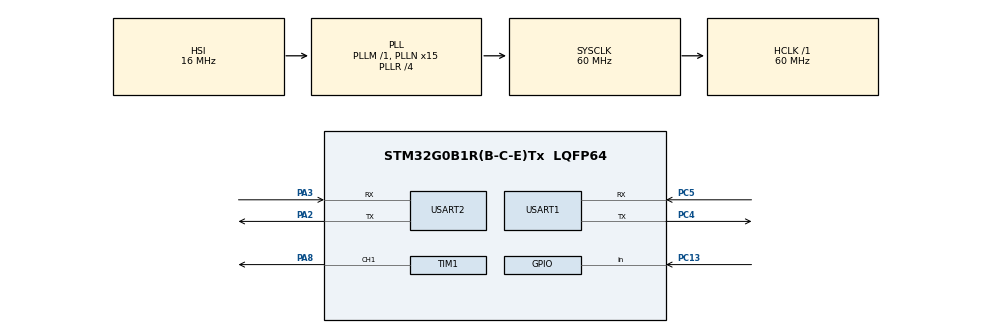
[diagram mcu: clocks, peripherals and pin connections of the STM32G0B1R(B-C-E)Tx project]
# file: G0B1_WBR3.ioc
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Dma.Request0=TIM1_CH1
Dma.TIM1_CH1.0.Direction=DMA_MEMORY_TO_PERIPH
Dma.TIM1_CH1.0.EventEnable=DISABLE
Dma.TIM1_CH1.0.Instance=DMA1_Channel1
Dma.TIM1_CH1.0.MemDataAlignment=DMA_MDATAALIGN_WORD
Dma.TIM1_CH1.0.MemInc=DMA_MINC_ENABLE
Dma.TIM1_CH1.0.Mode=DMA_NORMAL
Dma.TIM1_CH1.0.PeriphDataAlignment=DMA_PDATAALIGN_WORD
Dma.TIM1_CH1.0.PeriphInc=DMA_PINC_DISABLE
Dma.TIM1_CH1.0.Polarity=HAL_DMAMUX_REQ_GEN_RISING
Dma.TIM1_CH1.0.Priority=DMA_PRIORITY_HIGH
Dma.TIM1_CH1.0.RequestNumber=1
Dma.TIM1_CH1.0.SignalID=NONE
Dma.TIM1_CH1.0.SyncEnable=DISABLE
Dma.TIM1_CH1.0.SyncPolarity=HAL_DMAMUX_SYNC_NO_EVENT
Dma.TIM1_CH1.0.SyncRequestNumber=1
Dma.TIM1_CH1.0.SyncSignalID=NONE
Mcu.Family=STM32G0
Mcu.Name=STM32G0B1R(B-C-E)Tx
Mcu.Package=LQFP64
NVIC.DMA1_Channel1_IRQn=true\:0\:0\:false\:false\:true\:false\:true
NVIC.USART1_IRQn=true\:0\:0\:false\:false\:true\:true\:true
PA2.Mode=Asynchronous
PA2.Signal=USART2_TX
PA3.Mode=Asynchronous
PA3.Signal=USART2_RX
PA8.Signal=S_TIM1_CH1
PC13.Signal=GPIO_Input
PC4.Mode=Asynchronous
PC4.Signal=USART1_TX
PC5.Mode=Asynchronous
PC5.Signal=USART1_RX
ProjectManager.HeapSize=0x200
ProjectManager.StackSize=0x400
ProjectManager.TargetToolchain=MDK-ARM V5.32
RCC.ADCFreq_Value=60000000
RCC.AHBFreq_Value=60000000
RCC.CortexFreq_Value=60000000
RCC.EXTERNAL_CLOCK_VALUE=48000
RCC.HCLKFreq_Value=60000000
RCC.HSE_VALUE=8000000
RCC.HSI48_VALUE=48000000
RCC.HSI_VALUE=16000000
RCC.LSE_VALUE=32768
RCC.PLLN=15
RCC.PLLR=RCC_PLLR_DIV4
RCC.SYSCLKFreq_VALUE=60000000
RCC.SYSCLKSource=RCC_SYSCLKSOURCE_PLLCLK
RCC.USBFreq_Value=48000000
RCC.VCOOutputFreq_Value=240000000
SH.S_TIM1_CH1.0=TIM1_CH1,PWM Generation1 CH1
TIM1.Channel-PWM\ Generation1\ CH1=TIM_CHANNEL_1
TIM1.Period=24
TIM1.Prescaler=2
USART1.VirtualMode-Asynchronous=VM_ASYNC
USART2.VirtualMode-Asynchronous=VM_ASYNC
VP_SYS_VS_DBSignals.Mode=DisableDeadBatterySignals
board=custom

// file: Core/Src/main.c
/* USER CODE BEGIN Header */
/**
  ******************************************************************************
  * @file           : main.c
  * @brief          : Main program body
  ******************************************************************************
  * @attention
  *
  * <h2><center>&copy; Copyright (c) 2021 STMicroelectronics.
  * All rights reserved.</center></h2>
  *
  * This software component is licensed by ST under BSD 3-Clause license,
  * the "License"; You may not use this file except in compliance with the
  * License. You may obtain a copy of the License at:
  *                        opensource.org/licenses/BSD-3-Clause
  *
  ******************************************************************************
  */
/* USER CODE END Header */
#include "main.h"
#include "dma.h"
#include "tim.h"
#include "usart.h"
#include "gpio.h"

/* USER CODE BEGIN Includes */
#include "wifi.h"
#include "stdio.h"
/* USER CODE END Includes */

void SystemClock_Config(void);
/* USER CODE BEGIN PFP */
extern void user_button_init(void);
/* USER CODE END PFP */

int main(void)
{

  /* MCU Configuration--------------------------------------------------------*/

  /* Reset of all peripherals, Initializes the Flash interface and the Systick. */
  HAL_Init();

  /* Configure the system clock */
  SystemClock_Config();

  /* Initialize all configured peripherals */
  MX_GPIO_Init();
  MX_USART1_UART_Init();
  MX_DMA_Init();
  MX_TIM1_Init();
  MX_USART2_UART_Init();
  /* USER CODE BEGIN 2 */
  user_button_init();

  ws2812_init(&user_ws2812_control7, &htim1, TIM_CHANNEL_1);
  user_ws2812_control7.ws2812_updata(&user_ws2812_control7);

  wifi_protocol_init();
  HAL_Delay(50);
  all_data_update();
  /* USER CODE END 2 */

  /* Infinite loop */
  /* USER CODE BEGIN WHILE */
  while (1)
  {
      wifi_uart_service();
      Light_Updata_Loop();
    /* USER CODE END WHILE */

  }
}

void SystemClock_Config(void)
{
  RCC_OscInitTypeDef RCC_OscInitStruct = {0};
  RCC_ClkInitTypeDef RCC_ClkInitStruct = {0};
  RCC_PeriphCLKInitTypeDef PeriphClkInit = {0};

  /** Configure the main internal regulator output voltage
  */
  HAL_PWREx_ControlVoltageScaling(PWR_REGULATOR_VOLTAGE_SCALE1);
  /** Initializes the RCC Oscillators according to the specified parameters
  * in the RCC_OscInitTypeDef structure.
  */
  RCC_OscInitStruct.OscillatorType = RCC_OSCILLATORTYPE_HSI;
  RCC_OscInitStruct.HSIState = RCC_HSI_ON;
  RCC_OscInitStruct.HSIDiv = RCC_HSI_DIV1;
  RCC_OscInitStruct.HSICalibrationValue = RCC_HSICALIBRATION_DEFAULT;
  RCC_OscInitStruct.PLL.PLLState = RCC_PLL_ON;
  RCC_OscInitStruct.PLL.PLLSource = RCC_PLLSOURCE_HSI;
  RCC_OscInitStruct.PLL.PLLM = RCC_PLLM_DIV1;
  RCC_OscInitStruct.PLL.PLLN = 15;
  RCC_OscInitStruct.PLL.PLLP = RCC_PLLP_DIV2;
  RCC_OscInitStruct.PLL.PLLQ = RCC_PLLQ_DIV2;
  RCC_OscInitStruct.PLL.PLLR = RCC_PLLR_DIV4;
  if (HAL_RCC_OscConfig(&RCC_OscInitStruct) != HAL_OK)
  {
    Error_Handler();
  }
  /** Initializes the CPU, AHB and APB buses clocks
  */
  RCC_ClkInitStruct.ClockType = RCC_CLOCKTYPE_HCLK|RCC_CLOCKTYPE_SYSCLK
                              |RCC_CLOCKTYPE_PCLK1;
  RCC_ClkInitStruct.SYSCLKSource = RCC_SYSCLKSOURCE_PLLCLK;
  RCC_ClkInitStruct.AHBCLKDivider = RCC_SYSCLK_DIV1;
  RCC_ClkInitStruct.APB1CLKDivider = RCC_HCLK_DIV1;

  if (HAL_RCC_ClockConfig(&RCC_ClkInitStruct, FLASH_LATENCY_2) != HAL_OK)
  {
    Error_Handler();
  }
  /** Initializes the peripherals clocks
  */
  PeriphClkInit.PeriphClockSelection = RCC_PERIPHCLK_USART1|RCC_PERIPHCLK_USART2
                              |RCC_PERIPHCLK_TIM1;
  PeriphClkInit.Usart1ClockSelection = RCC_USART1CLKSOURCE_PCLK1;
  PeriphClkInit.Usart2ClockSelection = RCC_USART2CLKSOURCE_PCLK1;
  PeriphClkInit.Tim1ClockSelection = RCC_TIM1CLKSOURCE_PCLK1;
  if (HAL_RCCEx_PeriphCLKConfig(&PeriphClkInit) != HAL_OK)
  {
    Error_Handler();
  }
}

void Error_Handler(void)
{
  __disable_irq();
  while (1)
  {
  }
}

/************************ (C) COPYRIGHT STMicroelectronics *****END OF FILE****/
